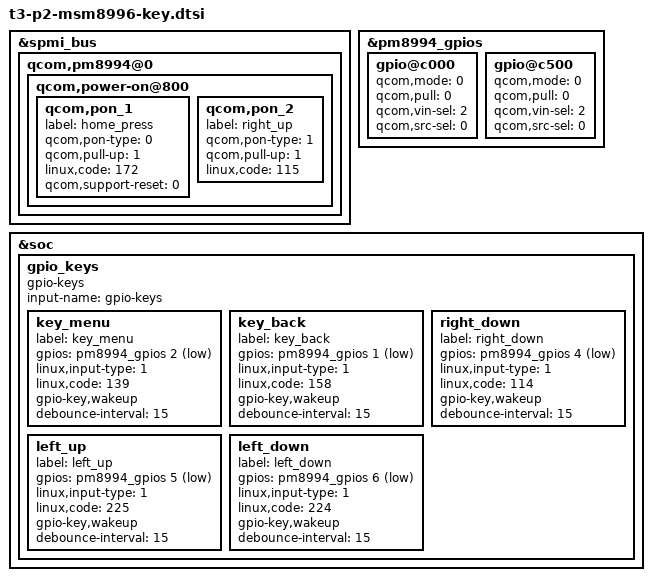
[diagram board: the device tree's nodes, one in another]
&spmi_bus {
	qcom,pm8994@0 {
		qcom,power-on@800 {
			/* Home press */
			qcom,pon_1 {
				label = "home_press";
				qcom,pon-type = <0>;
				qcom,pull-up = <1>;
				linux,code = <172>;
				qcom,support-reset = <0>;
			};

			/* Right up */
			qcom,pon_2 {
				label = "right_up";
				qcom,pon-type = <1>;
				qcom,pull-up = <1>;
				linux,code = <115>;
			};
		};
	};
};

&pm8994_gpios {
	gpio@c000 { /* GPIO 1 */
		qcom,mode = <0>;
		qcom,pull = <0>;
		qcom,vin-sel = <2>;
		qcom,src-sel = <0>;
		status = "okay";
	};

	gpio@c500 { /* GPIO 6 */
		qcom,mode = <0>;
		qcom,pull = <0>;
		qcom,vin-sel = <2>;
		qcom,src-sel = <0>;
		status = "okay";
	};
};

&soc {
	gpio_keys {
		compatible = "gpio-keys";
		input-name = "gpio-keys";

		key_menu {
			label = "key_menu";
			gpios = <&pm8994_gpios 2 0x1>;
			linux,input-type = <1>;
			linux,code = <139>;
			gpio-key,wakeup;
			debounce-interval = <15>;
		};

		key_back {
			label = "key_back";
			gpios = <&pm8994_gpios 1 0x1>;
			linux,input-type = <1>;
			linux,code = <158>;
			gpio-key,wakeup;
			debounce-interval = <15>;
		};

		/* Right down */
		right_down {
			label = "right_down";
			gpios = <&pm8994_gpios 4 0x1>;
			linux,input-type = <1>;
			linux,code = <114>;
			gpio-key,wakeup;
			debounce-interval = <15>;
		};

		/* Left up */
		left_up {
			label = "left_up";
			gpios = <&pm8994_gpios 5 0x1>;
			linux,input-type = <1>;
			linux,code = <225>;
			gpio-key,wakeup;
			debounce-interval = <15>;
		};

		/* Left down */
		left_down {
			label = "left_down";
			gpios = <&pm8994_gpios 6 0x1>;
			linux,input-type = <1>;
			linux,code = <224>;
			gpio-key,wakeup;
			debounce-interval = <15>;
		};
	};
};



